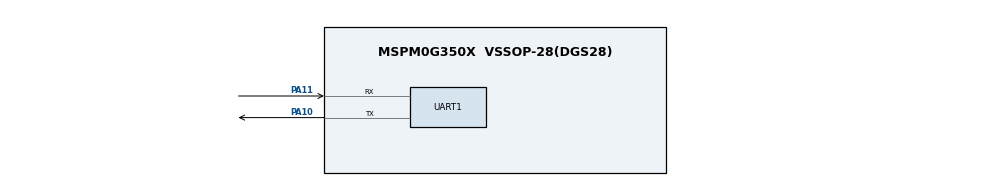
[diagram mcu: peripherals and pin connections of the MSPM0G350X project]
/**
 * @cliArgs --device "MSPM0G350X" --part "Default" --package "VSSOP-28(DGS28)" --product "mspm0_sdk@2.10.00.04"
 * @versions {"tool":"1.26.2+4477"}
 */

/**
 * Import the modules used in this configuration.
 */
const MCAN          = scripting.addModule("/ti/driverlib/MCAN", {}, false);
const MCAN1         = MCAN.addInstance();
const SYSCTL        = scripting.addModule("/ti/driverlib/SYSCTL");
const UART          = scripting.addModule("/ti/driverlib/UART", {}, false);
const UART1         = UART.addInstance();
const ProjectConfig = scripting.addModule("/ti/project_config/ProjectConfig");

/**
 * Write custom configuration values to the imported modules.
 */
MCAN1.$name                     = "MCAN0";
MCAN1.can_clk_freq_div          = "2";
MCAN1.desiredDataRate           = 2;
MCAN1.dataTimeSeg1_manual       = 15;
MCAN1.dataTimeSeg2_manual       = 4;
MCAN1.dataSynchJumpWidth_manual = 3;
MCAN1.rxFIFO0size               = 10;
MCAN1.dataRatePrescalar_manual  = 1;
MCAN1.nomRatePrescalar_manual   = 1;
MCAN1.nomTimeSeg1_manual        = 63;
MCAN1.nomTimeSeg2_manual        = 16;
MCAN1.nomSynchJumpWidth_manual  = 9;
MCAN1.wkupReqEnable             = true;
MCAN1.autoWkupEnable            = true;
MCAN1.emulationEnable           = true;
MCAN1.rrfe                      = true;
MCAN1.rrfs                      = true;
MCAN1.anfe                      = "1";
MCAN1.anfs                      = "1";
MCAN1.txFIFOSize                = 1;
MCAN1.spPercent                 = 80;
MCAN1.txPinConfig.$name         = "ti_driverlib_gpio_GPIOPinGeneric2";
MCAN1.rxPinConfig.$name         = "ti_driverlib_gpio_GPIOPinGeneric3";
scripting.suppress("80 Mhz MCAN frequency is reachable by selecting a smaller divider\\.", MCAN1, "can_clk_freq_div");

const Board = scripting.addModule("/ti/driverlib/Board", {}, false);

SYSCTL.SYSPLL_CLK1En         = true;
SYSCTL.HFCLK_Freq            = 8000000;
SYSCTL.HFCLKSource           = "HFXT";
SYSCTL.forceDefaultClkConfig = true;
SYSCTL.validateClkStatus     = true;
SYSCTL.CANCLKSource          = "SYSPLLCLK1";

UART1.$name                    = "UART_0";
UART1.targetBaudRate           = 1000000;
UART1.enableFIFO               = true;
UART1.peripheral.$assign       = "UART0";
UART1.peripheral.rxPin.$assign = "PA11";
UART1.peripheral.txPin.$assign = "PA10";
UART1.txPinConfig.$name        = "ti_driverlib_gpio_GPIOPinGeneric0";
UART1.rxPinConfig.$name        = "ti_driverlib_gpio_GPIOPinGeneric1";

ProjectConfig.migrationCondition = true;

/**
 * Pinmux solution for unlocked pins/peripherals. This ensures that minor changes to the automatic solver in a future
 * version of the tool will not impact the pinmux you originally saw.  These lines can be completely deleted in order to
 * re-solve from scratch.
 */
MCAN1.peripheral.$suggestSolution          = "CANFD0";
MCAN1.peripheral.rxPin.$suggestSolution    = "PA27";
MCAN1.peripheral.txPin.$suggestSolution    = "PA26";
Board.peripheral.$suggestSolution          = "DEBUGSS";
Board.peripheral.swclkPin.$suggestSolution = "PA20";
Board.peripheral.swdioPin.$suggestSolution = "PA19";
SYSCTL.peripheral.$suggestSolution         = "SYSCTL";
